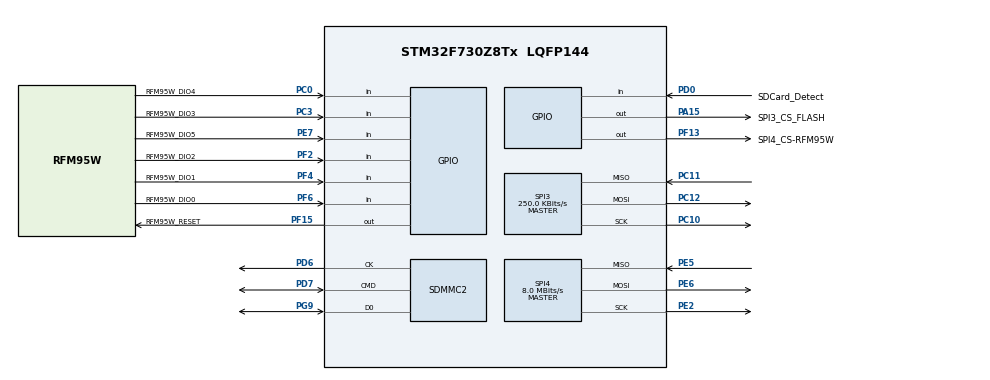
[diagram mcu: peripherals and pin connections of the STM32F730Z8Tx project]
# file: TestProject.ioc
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Dma.Request0=SDMMC2_RX
Dma.Request1=SDMMC2_TX
Dma.SDMMC2_RX.0.Direction=DMA_PERIPH_TO_MEMORY
Dma.SDMMC2_RX.0.FIFOMode=DMA_FIFOMODE_ENABLE
Dma.SDMMC2_RX.0.FIFOThreshold=DMA_FIFO_THRESHOLD_FULL
Dma.SDMMC2_RX.0.Instance=DMA2_Stream0
Dma.SDMMC2_RX.0.MemBurst=DMA_MBURST_INC4
Dma.SDMMC2_RX.0.MemDataAlignment=DMA_MDATAALIGN_WORD
Dma.SDMMC2_RX.0.MemInc=DMA_MINC_ENABLE
Dma.SDMMC2_RX.0.Mode=DMA_PFCTRL
Dma.SDMMC2_RX.0.PeriphBurst=DMA_PBURST_INC4
Dma.SDMMC2_RX.0.PeriphDataAlignment=DMA_PDATAALIGN_WORD
Dma.SDMMC2_RX.0.PeriphInc=DMA_PINC_DISABLE
Dma.SDMMC2_RX.0.Priority=DMA_PRIORITY_LOW
Dma.SDMMC2_TX.1.Direction=DMA_MEMORY_TO_PERIPH
Dma.SDMMC2_TX.1.FIFOMode=DMA_FIFOMODE_ENABLE
Dma.SDMMC2_TX.1.FIFOThreshold=DMA_FIFO_THRESHOLD_FULL
Dma.SDMMC2_TX.1.Instance=DMA2_Stream5
Dma.SDMMC2_TX.1.MemBurst=DMA_MBURST_INC4
Dma.SDMMC2_TX.1.MemDataAlignment=DMA_MDATAALIGN_WORD
Dma.SDMMC2_TX.1.MemInc=DMA_MINC_ENABLE
Dma.SDMMC2_TX.1.Mode=DMA_PFCTRL
Dma.SDMMC2_TX.1.PeriphBurst=DMA_PBURST_INC4
Dma.SDMMC2_TX.1.PeriphDataAlignment=DMA_PDATAALIGN_WORD
Dma.SDMMC2_TX.1.PeriphInc=DMA_PINC_DISABLE
Dma.SDMMC2_TX.1.Priority=DMA_PRIORITY_LOW
FATFS.BSP.number=1
FATFS.USE_DMA_CODE_SD=1
FATFS0.BSP.STBoard=false
FATFS0.BSP.api=Unknown
FATFS0.BSP.instance=PD0
FATFS0.BSP.ip=GPIO
FATFS0.BSP.mode=Input
FATFS0.BSP.name=Detect_SDIO
FATFS0.BSP.solution=PD0
Mcu.Family=STM32F7
Mcu.Name=STM32F730Z8Tx
Mcu.Package=LQFP144
NVIC.DMA2_Stream0_IRQn=true\:0\:0\:false\:false\:true\:false\:true\:true
NVIC.DMA2_Stream5_IRQn=true\:0\:0\:false\:false\:true\:false\:true\:true
NVIC.PriorityGroup=NVIC_PRIORITYGROUP_4
NVIC.SDMMC2_IRQn=true\:0\:0\:false\:false\:true\:true\:true\:true
PA15.GPIO_Label=SPI3_CS_FLASH
PA15.Signal=GPIO_Output
PC0.GPIO_Label=RFM95W_DIO4
PC0.Signal=GPIO_Input
PC10.Mode=Full_Duplex_Master
PC10.Signal=SPI3_SCK
PC11.Mode=Full_Duplex_Master
PC11.Signal=SPI3_MISO
PC12.Mode=Full_Duplex_Master
PC12.Signal=SPI3_MOSI
PC3.GPIO_Label=RFM95W_DIO3
PC3.Signal=GPIO_Input
PD0.GPIO_Label=SDCard_Detect
PD0.Signal=GPIO_Input
PD6.Mode=SD_1_bit
PD6.Signal=SDMMC2_CK
PD7.Mode=SD_1_bit
PD7.Signal=SDMMC2_CMD
PE2.Mode=Full_Duplex_Master
PE2.Signal=SPI4_SCK
PE5.Mode=Full_Duplex_Master
PE5.Signal=SPI4_MISO
PE6.Mode=Full_Duplex_Master
PE6.Signal=SPI4_MOSI
PE7.GPIO_Label=RFM95W_DIO5
PE7.Signal=GPIO_Input
PF13.GPIO_Label=SPI4_CS-RFM95W
PF13.Signal=GPIO_Output
PF15.GPIO_Label=RFM95W_RESET
PF15.PinState=GPIO_PIN_SET
PF15.Signal=GPIO_Output
PF2.GPIO_Label=RFM95W_DIO2
PF2.Signal=GPIO_Input
PF4.GPIO_Label=RFM95W_DIO1
PF4.Signal=GPIO_Input
PF6.GPIO_Label=RFM95W_DIO0
PF6.Signal=GPIO_Input
PG9.Mode=SD_1_bit
PG9.Signal=SDMMC2_D0
ProjectManager.HeapSize=0x200
ProjectManager.StackSize=0x400
ProjectManager.TargetToolchain=STM32CubeIDE
RCC.HSE_VALUE=25000000
RCC.HSI_VALUE=16000000
RCC.LSE_VALUE=32768
RCC.USBFreq_Value=96000000
RCC.VCOOutputFreq_Value=192000000
SPI3.BaudRatePrescaler=SPI_BAUDRATEPRESCALER_64
SPI3.CalculateBaudRate=250.0 KBits/s
SPI3.DataSize=SPI_DATASIZE_8BIT
SPI3.Direction=SPI_DIRECTION_2LINES
SPI3.Mode=SPI_MODE_MASTER
SPI3.NSSPMode=SPI_NSS_PULSE_DISABLE
SPI3.VirtualType=VM_MASTER
SPI4.BaudRatePrescaler=SPI_BAUDRATEPRESCALER_2
SPI4.CalculateBaudRate=8.0 MBits/s
SPI4.DataSize=SPI_DATASIZE_8BIT
SPI4.Direction=SPI_DIRECTION_2LINES
SPI4.Mode=SPI_MODE_MASTER
SPI4.NSSPMode=SPI_NSS_PULSE_DISABLE
SPI4.VirtualType=VM_MASTER
VP_FATFS_VS_SDIO.Mode=SDIO
board=custom

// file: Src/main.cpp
/* USER CODE BEGIN Header */
/**
  ******************************************************************************
  * @file           : main.c
  * @brief          : Main program body
  ******************************************************************************
  * @attention
  *
  * Copyright (c) 2023 STMicroelectronics.
  * All rights reserved.
  *
  * This software is licensed under terms that can be found in the LICENSE file
  * in the root directory of this software component.
  * If no LICENSE file comes with this software, it is provided AS-IS.
  *
  ******************************************************************************
  */
/* USER CODE END Header */
#include "main.h"
#include "fatfs.h"

SD_HandleTypeDef hsd2;
DMA_HandleTypeDef hdma_sdmmc2_rx;
DMA_HandleTypeDef hdma_sdmmc2_tx;

SPI_HandleTypeDef hspi3;
SPI_HandleTypeDef hspi4;

void SystemClock_Config(void);
static void MX_GPIO_Init(void);
static void MX_DMA_Init(void);
static void MX_SDMMC2_SD_Init(void);
static void MX_SPI4_Init(void);
static void MX_SPI3_Init(void);

int main(void)
{

  /* MCU Configuration--------------------------------------------------------*/

  /* Reset of all peripherals, Initializes the Flash interface and the Systick. */
  HAL_Init();

  /* Configure the system clock */
  SystemClock_Config();

  /* Initialize all configured peripherals */
  MX_GPIO_Init();
  MX_DMA_Init();
  MX_SDMMC2_SD_Init();
  MX_SPI4_Init();
  MX_SPI3_Init();
  MX_FATFS_Init();
  /* USER CODE BEGIN 2 */
	int a = 0;

  /* USER CODE END 2 */

  /* Infinite loop */
  /* USER CODE BEGIN WHILE */
  while (1)
  {
	a++;
    /* USER CODE END WHILE */

  }
}

void SystemClock_Config(void)
{
  RCC_OscInitTypeDef RCC_OscInitStruct = {0};
  RCC_ClkInitTypeDef RCC_ClkInitStruct = {0};

  /** Configure the main internal regulator output voltage
  */
  __HAL_RCC_PWR_CLK_ENABLE();
  __HAL_PWR_VOLTAGESCALING_CONFIG(PWR_REGULATOR_VOLTAGE_SCALE3);

  /** Initializes the RCC Oscillators according to the specified parameters
  * in the RCC_OscInitTypeDef structure.
  */
  RCC_OscInitStruct.OscillatorType = RCC_OSCILLATORTYPE_HSI;
  RCC_OscInitStruct.HSIState = RCC_HSI_ON;
  RCC_OscInitStruct.HSICalibrationValue = RCC_HSICALIBRATION_DEFAULT;
  RCC_OscInitStruct.PLL.PLLState = RCC_PLL_NONE;
  if (HAL_RCC_OscConfig(&RCC_OscInitStruct) != HAL_OK)
  {
    Error_Handler();
  }

  /** Initializes the CPU, AHB and APB buses clocks
  */
  RCC_ClkInitStruct.ClockType = RCC_CLOCKTYPE_HCLK|RCC_CLOCKTYPE_SYSCLK
                              |RCC_CLOCKTYPE_PCLK1|RCC_CLOCKTYPE_PCLK2;
  RCC_ClkInitStruct.SYSCLKSource = RCC_SYSCLKSOURCE_HSI;
  RCC_ClkInitStruct.AHBCLKDivider = RCC_SYSCLK_DIV1;
  RCC_ClkInitStruct.APB1CLKDivider = RCC_HCLK_DIV1;
  RCC_ClkInitStruct.APB2CLKDivider = RCC_HCLK_DIV1;

  if (HAL_RCC_ClockConfig(&RCC_ClkInitStruct, FLASH_LATENCY_0) != HAL_OK)
  {
    Error_Handler();
  }
}

static void MX_SDMMC2_SD_Init(void)
{

  hsd2.Instance = SDMMC2;
  hsd2.Init.ClockEdge = SDMMC_CLOCK_EDGE_RISING;
  hsd2.Init.ClockBypass = SDMMC_CLOCK_BYPASS_DISABLE;
  hsd2.Init.ClockPowerSave = SDMMC_CLOCK_POWER_SAVE_DISABLE;
  hsd2.Init.BusWide = SDMMC_BUS_WIDE_1B;
  hsd2.Init.HardwareFlowControl = SDMMC_HARDWARE_FLOW_CONTROL_DISABLE;
  hsd2.Init.ClockDiv = 0;

}

static void MX_SPI3_Init(void)
{

  /* SPI3 parameter configuration*/
  hspi3.Instance = SPI3;
  hspi3.Init.Mode = SPI_MODE_MASTER;
  hspi3.Init.Direction = SPI_DIRECTION_2LINES;
  hspi3.Init.DataSize = SPI_DATASIZE_8BIT;
  hspi3.Init.CLKPolarity = SPI_POLARITY_LOW;
  hspi3.Init.CLKPhase = SPI_PHASE_1EDGE;
  hspi3.Init.NSS = SPI_NSS_SOFT;
  hspi3.Init.BaudRatePrescaler = SPI_BAUDRATEPRESCALER_64;
  hspi3.Init.FirstBit = SPI_FIRSTBIT_MSB;
  hspi3.Init.TIMode = SPI_TIMODE_DISABLE;
  hspi3.Init.CRCCalculation = SPI_CRCCALCULATION_DISABLE;
  hspi3.Init.CRCPolynomial = 7;
  hspi3.Init.CRCLength = SPI_CRC_LENGTH_DATASIZE;
  hspi3.Init.NSSPMode = SPI_NSS_PULSE_DISABLE;
  if (HAL_SPI_Init(&hspi3) != HAL_OK)
  {
    Error_Handler();
  }

}

static void MX_SPI4_Init(void)
{

  /* SPI4 parameter configuration*/
  hspi4.Instance = SPI4;
  hspi4.Init.Mode = SPI_MODE_MASTER;
  hspi4.Init.Direction = SPI_DIRECTION_2LINES;
  hspi4.Init.DataSize = SPI_DATASIZE_8BIT;
  hspi4.Init.CLKPolarity = SPI_POLARITY_LOW;
  hspi4.Init.CLKPhase = SPI_PHASE_1EDGE;
  hspi4.Init.NSS = SPI_NSS_SOFT;
  hspi4.Init.BaudRatePrescaler = SPI_BAUDRATEPRESCALER_2;
  hspi4.Init.FirstBit = SPI_FIRSTBIT_MSB;
  hspi4.Init.TIMode = SPI_TIMODE_DISABLE;
  hspi4.Init.CRCCalculation = SPI_CRCCALCULATION_DISABLE;
  hspi4.Init.CRCPolynomial = 7;
  hspi4.Init.CRCLength = SPI_CRC_LENGTH_DATASIZE;
  hspi4.Init.NSSPMode = SPI_NSS_PULSE_DISABLE;
  if (HAL_SPI_Init(&hspi4) != HAL_OK)
  {
    Error_Handler();
  }

}

static void MX_DMA_Init(void)
{

  /* DMA controller clock enable */
  __HAL_RCC_DMA2_CLK_ENABLE();

  /* DMA interrupt init */
  /* DMA2_Stream0_IRQn interrupt configuration */
  HAL_NVIC_SetPriority(DMA2_Stream0_IRQn, 0, 0);
  HAL_NVIC_EnableIRQ(DMA2_Stream0_IRQn);
  /* DMA2_Stream5_IRQn interrupt configuration */
  HAL_NVIC_SetPriority(DMA2_Stream5_IRQn, 0, 0);
  HAL_NVIC_EnableIRQ(DMA2_Stream5_IRQn);

}

static void MX_GPIO_Init(void)
{
  GPIO_InitTypeDef GPIO_InitStruct = {0};

  /* GPIO Ports Clock Enable */
  __HAL_RCC_GPIOE_CLK_ENABLE();
  __HAL_RCC_GPIOF_CLK_ENABLE();
  __HAL_RCC_GPIOC_CLK_ENABLE();
  __HAL_RCC_GPIOA_CLK_ENABLE();
  __HAL_RCC_GPIOD_CLK_ENABLE();
  __HAL_RCC_GPIOG_CLK_ENABLE();

  /*Configure GPIO pin Output Level */
  HAL_GPIO_WritePin(SPI4_CS_RFM95W_GPIO_Port, SPI4_CS_RFM95W_Pin, GPIO_PIN_RESET);

  /*Configure GPIO pin Output Level */
  HAL_GPIO_WritePin(RFM95W_RESET_GPIO_Port, RFM95W_RESET_Pin, GPIO_PIN_SET);

  /*Configure GPIO pin Output Level */
  HAL_GPIO_WritePin(SPI3_CS_FLASH_GPIO_Port, SPI3_CS_FLASH_Pin, GPIO_PIN_RESET);

  /*Configure GPIO pins : RFM95W_DIO2_Pin RFM95W_DIO1_Pin RFM95W_DIO0_Pin */
  GPIO_InitStruct.Pin = RFM95W_DIO2_Pin|RFM95W_DIO1_Pin|RFM95W_DIO0_Pin;
  GPIO_InitStruct.Mode = GPIO_MODE_INPUT;
  GPIO_InitStruct.Pull = GPIO_NOPULL;
  HAL_GPIO_Init(GPIOF, &GPIO_InitStruct);

  /*Configure GPIO pins : RFM95W_DIO4_Pin RFM95W_DIO3_Pin */
  GPIO_InitStruct.Pin = RFM95W_DIO4_Pin|RFM95W_DIO3_Pin;
  GPIO_InitStruct.Mode = GPIO_MODE_INPUT;
  GPIO_InitStruct.Pull = GPIO_NOPULL;
  HAL_GPIO_Init(GPIOC, &GPIO_InitStruct);

  /*Configure GPIO pins : SPI4_CS_RFM95W_Pin RFM95W_RESET_Pin */
  GPIO_InitStruct.Pin = SPI4_CS_RFM95W_Pin|RFM95W_RESET_Pin;
  GPIO_InitStruct.Mode = GPIO_MODE_OUTPUT_PP;
  GPIO_InitStruct.Pull = GPIO_NOPULL;
  GPIO_InitStruct.Speed = GPIO_SPEED_FREQ_LOW;
  HAL_GPIO_Init(GPIOF, &GPIO_InitStruct);

  /*Configure GPIO pin : RFM95W_DIO5_Pin */
  GPIO_InitStruct.Pin = RFM95W_DIO5_Pin;
  GPIO_InitStruct.Mode = GPIO_MODE_INPUT;
  GPIO_InitStruct.Pull = GPIO_NOPULL;
  HAL_GPIO_Init(RFM95W_DIO5_GPIO_Port, &GPIO_InitStruct);

  /*Configure GPIO pin : SPI3_CS_FLASH_Pin */
  GPIO_InitStruct.Pin = SPI3_CS_FLASH_Pin;
  GPIO_InitStruct.Mode = GPIO_MODE_OUTPUT_PP;
  GPIO_InitStruct.Pull = GPIO_NOPULL;
  GPIO_InitStruct.Speed = GPIO_SPEED_FREQ_LOW;
  HAL_GPIO_Init(SPI3_CS_FLASH_GPIO_Port, &GPIO_InitStruct);

  /*Configure GPIO pin : SDCard_Detect_Pin */
  GPIO_InitStruct.Pin = SDCard_Detect_Pin;
  GPIO_InitStruct.Mode = GPIO_MODE_INPUT;
  GPIO_InitStruct.Pull = GPIO_NOPULL;
  HAL_GPIO_Init(SDCard_Detect_GPIO_Port, &GPIO_InitStruct);

}

void Error_Handler(void)
{
  __disable_irq();
  while (1)
  {
  }
}
